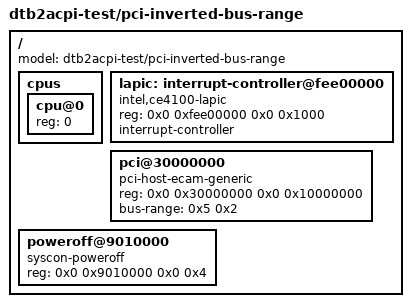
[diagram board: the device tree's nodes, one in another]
/dts-v1/;

/* bus-range with start > end — must error as MalformedProperty
 * (the bus_start > bus_end branch in extract_mcfg, distinct from the
 * ValueOutOfRange branch covered by bus_range_too_big).
 */
/ {
	#address-cells = <2>;
	#size-cells = <2>;
	model = "dtb2acpi-test/pci-inverted-bus-range";

	cpus {
		#address-cells = <1>;
		#size-cells = <0>;

		cpu@0 {
			device_type = "cpu";
			reg = <0>;
		};
	};

		lapic: interrupt-controller@fee00000 {
		compatible = "intel,ce4100-lapic";
		reg = <0x0 0xfee00000 0x0 0x1000>;
		interrupt-controller;
		#interrupt-cells = <2>;
	};

	pci@30000000 {
		compatible = "pci-host-ecam-generic";
		#address-cells = <3>;
		#size-cells = <2>;
		reg = <0x0 0x30000000 0x0 0x10000000>;
		bus-range = <0x5 0x2>;
	};
		poweroff@9010000 {
		compatible = "syscon-poweroff";
		reg = <0x0 0x9010000 0x0 0x4>;
	};
};
